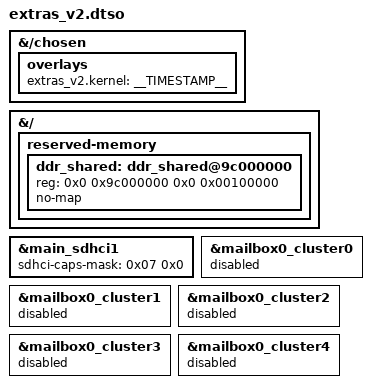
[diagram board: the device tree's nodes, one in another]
/dts-v1/;
/plugin/;

&{/chosen} {
	overlays {
		extras_v2.kernel = __TIMESTAMP__;
	};
};

&{/} {
    reserved-memory {
        #address-cells = <2>;
        #size-cells = <2>;
        ranges;

        ddr_shared: ddr_shared@9c000000 {
            reg = <0x0 0x9c000000 0x0 0x00100000>; // 1MB at 0x9C000000
            no-map;
            status = "okay";
        };
    };
};

&main_sdhci1 {
    sdhci-caps-mask = <0x07 0x0>;
};

&mailbox0_cluster0 {
	status = "disabled";
};

&mailbox0_cluster1 {
	status = "disabled";
};

&mailbox0_cluster2 {
	status = "disabled";
};

&mailbox0_cluster3 {
	status = "disabled";
};

&mailbox0_cluster4 {
	status = "disabled";
};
